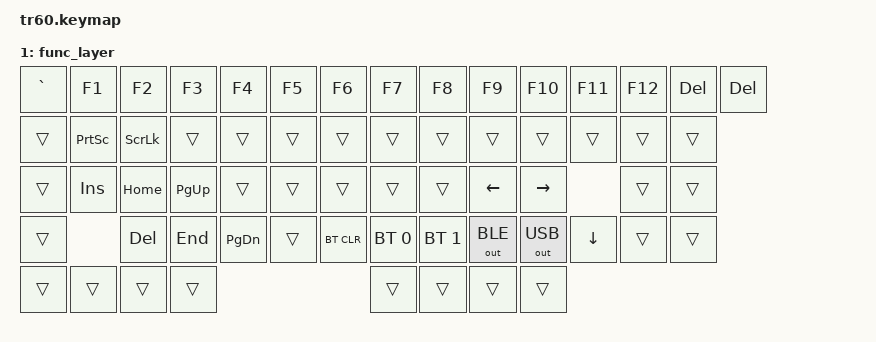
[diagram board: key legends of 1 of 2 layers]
/*
 * Copyright (c) 2023 Srishtik Bhandarkar
 *
 * SPDX-License-Identifier: MIT
 */

#include <behaviors.dtsi>
#include <dt-bindings/zmk/keys.h>
#include <dt-bindings/zmk/bt.h>
#include <dt-bindings/zmk/outputs.h>

/ {
    keymap {
        compatible = "zmk,keymap";

        default_layer {
            // ------------------------------------------------------------------------------------------
            // | ESC |  1  |  2  |  3  |  4  |  5  |  6  |  7  |  8  |  9  |  0  |  -  |  =  |   BKSP   |
            // | TAB  |  Q  |  W  |  E  |  R  |  T  |  Y  |  U  |  I  |  O  |  P  |  [  |  ]  |   "|"   |
            // | CAPS  |  A  |  S  |  D  |  F  |  G  |  H  |  J  |  K  |  L  |  ;  |  '  |     ENTER    |
            // |  SHIFT  |  Z  |  X  |  C  |  V  |  B  |  N  |  M  |  ,  |  .  |  /  |    SHIFT  | MO(1)|
            // |  CTL  |  WIN  |  ALT  |            SPACE                      |  ALT  |  WIN   |  CTL  |
            // ------------------------------------------------------------------------------------------
            bindings = <
            &gresc  &kp F1      &kp F2      &kp F3      &kp F4      &kp F5      &bootloader
            &kp GRAVE  &kp N1 &kp N2 &kp N3 &kp N4 &kp N5 &kp N6 
            &kp TAB  &kp Q  &kp W  &kp E  &kp R  &kp T  
            &kp CLCK  &kp A  &kp S  &kp D  &kp F  &kp G 
            &kp LSHFT   &kp Z  &kp X  &kp C  &kp V  
            &kp LCTRL &kp LGUI &kp LALT             &kp SPACE                   
            >;
        };

        func_layer {
            // ------------------------------------------------------------------------------------------
            // | ~    | F1  | F2  | F3  | F4  | F5  | F6  | F7  | F8  | F9  | F10  | F11 | F12 |    DEL  |
            // |      | PSCRN | SLCK | |  |  |  |  |   |     |    |  UP  |       |             |
            // |   |INSERT | HOME | PG_UP |    |    |  |  |   |     |  LEFT  |   RIGHT   |               |
            // |        |  DEL  | END  | PG_DN |    |BT_CLR||BS_1|OUT_BLE|OUT_USB|DOWN |     |           |
            // |        |       |      |                                     |       |       |     |     |
            // -------------------------------------------------------------------------------------------
            bindings = <
            &kp GRAVE   &kp F1      &kp F2      &kp F3      &kp F4      &kp F5      &kp F6      &kp F7       &kp F8       &kp F9       &kp F10      &kp F11     &kp F12     &kp DEL     &kp DEL
            &trans      &kp PSCRN   &kp SLCK    &trans      &trans      &trans      &trans      &trans       &trans       &trans       &trans       &trans      &trans      &trans
            &trans      &kp INS     &kp HOME    &kp PG_UP   &trans      &trans      &trans      &trans       &trans       &kp LEFT     &kp RIGHT                &trans      &trans
            &trans                  &kp DEL     &kp END     &kp PG_DN   &trans      &bt BT_CLR  &bt BT_SEL 0 &bt BT_SEL 1 &out OUT_BLE &out OUT_USB &kp DOWN    &trans      &trans
            &trans      &trans      &trans                                           &trans     &trans       &trans       &trans       &trans
            >;
        };
    };
};
